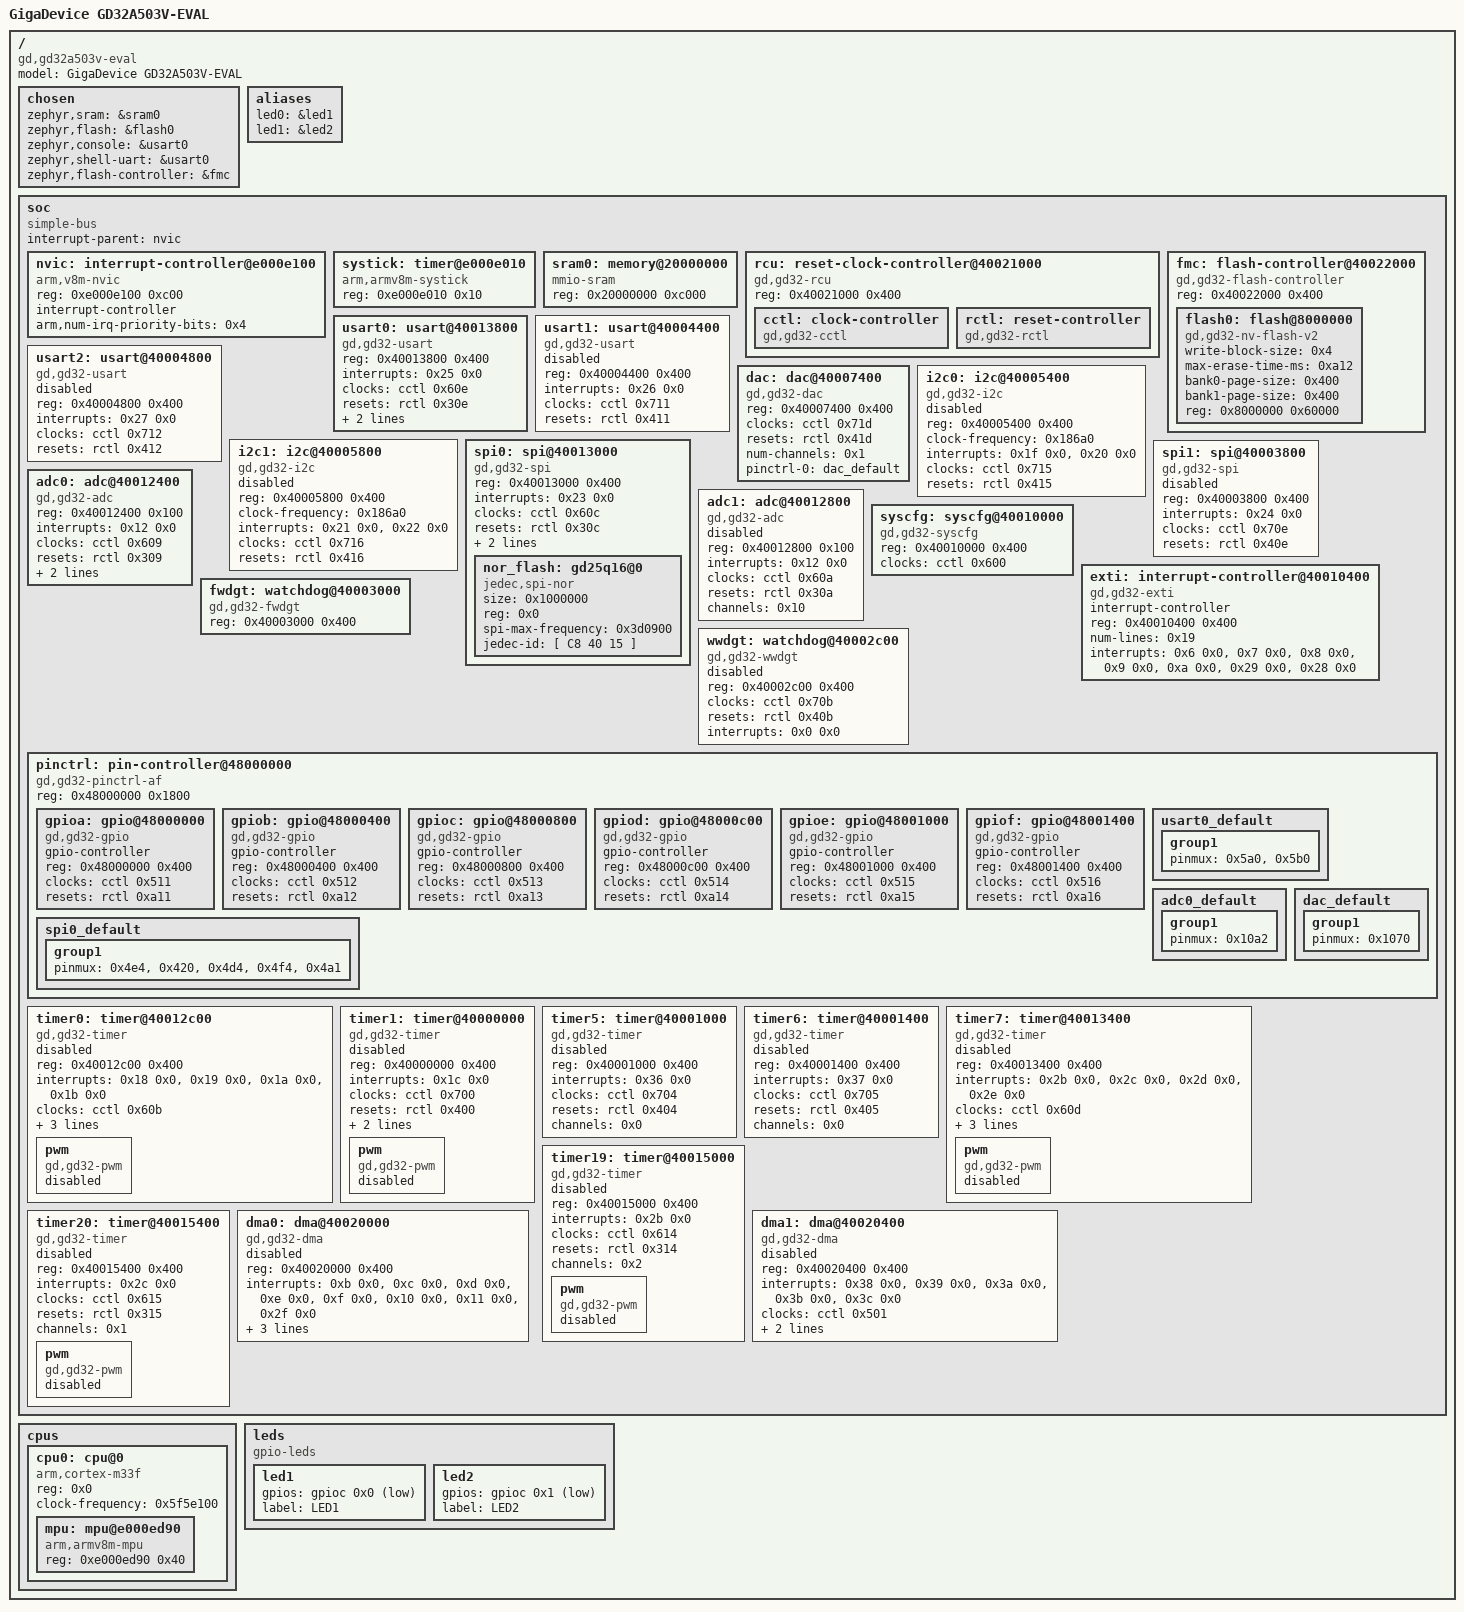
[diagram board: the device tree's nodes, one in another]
/dts-v1/;

/* node '/' defined in zephyr/dts/common/skeleton.dtsi:9 */
/ {
	#address-cells = < 0x1 >;            /* in zephyr/dts/common/skeleton.dtsi:10 */
	#size-cells = < 0x1 >;               /* in zephyr/dts/common/skeleton.dtsi:11 */
	model = "GigaDevice GD32A503V-EVAL"; /* in zephyr/boards/gd/gd32a503v_eval/gd32a503v_eval.dts:12 */
	compatible = "gd,gd32a503v-eval";    /* in zephyr/boards/gd/gd32a503v_eval/gd32a503v_eval.dts:13 */

	/* node '/chosen' defined in zephyr/dts/common/skeleton.dtsi:13 */
	chosen {
		zephyr,sram = &sram0;           /* in zephyr/boards/gd/gd32a503v_eval/gd32a503v_eval.dts:16 */
		zephyr,flash = &flash0;         /* in zephyr/boards/gd/gd32a503v_eval/gd32a503v_eval.dts:17 */
		zephyr,console = &usart0;       /* in zephyr/boards/gd/gd32a503v_eval/gd32a503v_eval.dts:18 */
		zephyr,shell-uart = &usart0;    /* in zephyr/boards/gd/gd32a503v_eval/gd32a503v_eval.dts:19 */
		zephyr,flash-controller = &fmc; /* in zephyr/boards/gd/gd32a503v_eval/gd32a503v_eval.dts:20 */
	};

	/* node '/aliases' defined in zephyr/dts/common/skeleton.dtsi:15 */
	aliases {
		led0 = &led1; /* in zephyr/boards/gd/gd32a503v_eval/gd32a503v_eval.dts:38 */
		led1 = &led2; /* in zephyr/boards/gd/gd32a503v_eval/gd32a503v_eval.dts:39 */
	};

	/* node '/soc' defined in zephyr/dts/arm/armv8-m.dtsi:6 */
	soc {
		#address-cells = < 0x1 >;     /* in zephyr/dts/arm/armv8-m.dtsi:7 */
		#size-cells = < 0x1 >;        /* in zephyr/dts/arm/armv8-m.dtsi:8 */
		compatible = "simple-bus";    /* in zephyr/dts/arm/armv8-m.dtsi:9 */
		interrupt-parent = < &nvic >; /* in zephyr/dts/arm/armv8-m.dtsi:10 */
		ranges;                       /* in zephyr/dts/arm/armv8-m.dtsi:11 */

		/* node '/soc/interrupt-controller@e000e100' defined in zephyr/dts/arm/armv8-m.dtsi:13 */
		nvic: interrupt-controller@e000e100 {
			#address-cells = < 0x1 >;            /* in zephyr/dts/arm/armv8-m.dtsi:14 */
			compatible = "arm,v8m-nvic";         /* in zephyr/dts/arm/armv8-m.dtsi:15 */
			reg = < 0xe000e100 0xc00 >;          /* in zephyr/dts/arm/armv8-m.dtsi:16 */
			interrupt-controller;                /* in zephyr/dts/arm/armv8-m.dtsi:17 */
			#interrupt-cells = < 0x2 >;          /* in zephyr/dts/arm/armv8-m.dtsi:18 */
			arm,num-irq-priority-bits = < 0x4 >; /* in zephyr/dts/arm/gd/gd32a50x/gd32a50x.dtsi:420 */
			phandle = < 0x1 >;                   /* in zephyr/dts/arm/armv8-m.dtsi:10 */
		};

		/* node '/soc/timer@e000e010' defined in zephyr/dts/arm/armv8-m.dtsi:21 */
		systick: timer@e000e010 {
			compatible = "arm,armv8m-systick"; /* in zephyr/dts/arm/armv8-m.dtsi:22 */
			reg = < 0xe000e010 0x10 >;         /* in zephyr/dts/arm/armv8-m.dtsi:23 */
		};

		/* node '/soc/memory@20000000' defined in zephyr/dts/arm/gd/gd32a50x/gd32a50x.dtsi:36 */
		sram0: memory@20000000 {
			compatible = "mmio-sram";    /* in zephyr/dts/arm/gd/gd32a50x/gd32a50x.dtsi:37 */
			reg = < 0x20000000 0xc000 >; /* in zephyr/dts/arm/gd/gd32a50x/gd32a503vdt3.dtsi:15 */
		};

		/* node '/soc/reset-clock-controller@40021000' defined in zephyr/dts/arm/gd/gd32a50x/gd32a50x.dtsi:40 */
		rcu: reset-clock-controller@40021000 {
			compatible = "gd,gd32-rcu"; /* in zephyr/dts/arm/gd/gd32a50x/gd32a50x.dtsi:41 */
			reg = < 0x40021000 0x400 >; /* in zephyr/dts/arm/gd/gd32a50x/gd32a50x.dtsi:42 */
			status = "okay";            /* in zephyr/dts/arm/gd/gd32a50x/gd32a50x.dtsi:43 */

			/* node '/soc/reset-clock-controller@40021000/clock-controller' defined in zephyr/dts/arm/gd/gd32a50x/gd32a50x.dtsi:45 */
			cctl: clock-controller {
				compatible = "gd,gd32-cctl"; /* in zephyr/dts/arm/gd/gd32a50x/gd32a50x.dtsi:46 */
				#clock-cells = < 0x1 >;      /* in zephyr/dts/arm/gd/gd32a50x/gd32a50x.dtsi:47 */
				status = "okay";             /* in zephyr/dts/arm/gd/gd32a50x/gd32a50x.dtsi:48 */
				phandle = < 0x2 >;           /* in zephyr/dts/arm/gd/gd32a50x/gd32a50x.dtsi:78 */
			};

			/* node '/soc/reset-clock-controller@40021000/reset-controller' defined in zephyr/dts/arm/gd/gd32a50x/gd32a50x.dtsi:51 */
			rctl: reset-controller {
				compatible = "gd,gd32-rctl"; /* in zephyr/dts/arm/gd/gd32a50x/gd32a50x.dtsi:52 */
				#reset-cells = < 0x1 >;      /* in zephyr/dts/arm/gd/gd32a50x/gd32a50x.dtsi:53 */
				status = "okay";             /* in zephyr/dts/arm/gd/gd32a50x/gd32a50x.dtsi:54 */
				phandle = < 0x3 >;           /* in zephyr/dts/arm/gd/gd32a50x/gd32a50x.dtsi:79 */
			};
		};

		/* node '/soc/flash-controller@40022000' defined in zephyr/dts/arm/gd/gd32a50x/gd32a50x.dtsi:58 */
		fmc: flash-controller@40022000 {
			compatible = "gd,gd32-flash-controller"; /* in zephyr/dts/arm/gd/gd32a50x/gd32a50x.dtsi:59 */
			reg = < 0x40022000 0x400 >;              /* in zephyr/dts/arm/gd/gd32a50x/gd32a50x.dtsi:60 */
			#address-cells = < 0x1 >;                /* in zephyr/dts/arm/gd/gd32a50x/gd32a50x.dtsi:62 */
			#size-cells = < 0x1 >;                   /* in zephyr/dts/arm/gd/gd32a50x/gd32a50x.dtsi:63 */

			/* node '/soc/flash-controller@40022000/flash@8000000' defined in zephyr/dts/arm/gd/gd32a50x/gd32a50x.dtsi:65 */
			flash0: flash@8000000 {
				compatible = "gd,gd32-nv-flash-v2",
				             "soc-nv-flash";        /* in zephyr/dts/arm/gd/gd32a50x/gd32a50x.dtsi:66 */
				write-block-size = < 0x4 >;         /* in zephyr/dts/arm/gd/gd32a50x/gd32a50x.dtsi:67 */
				max-erase-time-ms = < 0xa12 >;      /* in zephyr/dts/arm/gd/gd32a50x/gd32a50x.dtsi:68 */
				bank0-page-size = < 0x400 >;        /* in zephyr/dts/arm/gd/gd32a50x/gd32a50x.dtsi:69 */
				bank1-page-size = < 0x400 >;        /* in zephyr/dts/arm/gd/gd32a50x/gd32a50x.dtsi:70 */
				reg = < 0x8000000 0x60000 >;        /* in zephyr/dts/arm/gd/gd32a50x/gd32a503vdt3.dtsi:11 */
			};
		};

		/* node '/soc/usart@40013800' defined in zephyr/dts/arm/gd/gd32a50x/gd32a50x.dtsi:74 */
		usart0: usart@40013800 {
			compatible = "gd,gd32-usart";    /* in zephyr/dts/arm/gd/gd32a50x/gd32a50x.dtsi:75 */
			reg = < 0x40013800 0x400 >;      /* in zephyr/dts/arm/gd/gd32a50x/gd32a50x.dtsi:76 */
			interrupts = < 0x25 0x0 >;       /* in zephyr/dts/arm/gd/gd32a50x/gd32a50x.dtsi:77 */
			clocks = < &cctl 0x60e >;        /* in zephyr/dts/arm/gd/gd32a50x/gd32a50x.dtsi:78 */
			resets = < &rctl 0x30e >;        /* in zephyr/dts/arm/gd/gd32a50x/gd32a50x.dtsi:79 */
			status = "okay";                 /* in zephyr/boards/gd/gd32a503v_eval/gd32a503v_eval.dts:68 */
			current-speed = < 0x1c200 >;     /* in zephyr/boards/gd/gd32a503v_eval/gd32a503v_eval.dts:69 */
			pinctrl-0 = < &usart0_default >; /* in zephyr/boards/gd/gd32a503v_eval/gd32a503v_eval.dts:70 */
			pinctrl-names = "default";       /* in zephyr/boards/gd/gd32a503v_eval/gd32a503v_eval.dts:71 */
		};

		/* node '/soc/usart@40004400' defined in zephyr/dts/arm/gd/gd32a50x/gd32a50x.dtsi:83 */
		usart1: usart@40004400 {
			compatible = "gd,gd32-usart"; /* in zephyr/dts/arm/gd/gd32a50x/gd32a50x.dtsi:84 */
			reg = < 0x40004400 0x400 >;   /* in zephyr/dts/arm/gd/gd32a50x/gd32a50x.dtsi:85 */
			interrupts = < 0x26 0x0 >;    /* in zephyr/dts/arm/gd/gd32a50x/gd32a50x.dtsi:86 */
			clocks = < &cctl 0x711 >;     /* in zephyr/dts/arm/gd/gd32a50x/gd32a50x.dtsi:87 */
			resets = < &rctl 0x411 >;     /* in zephyr/dts/arm/gd/gd32a50x/gd32a50x.dtsi:88 */
			status = "disabled";          /* in zephyr/dts/arm/gd/gd32a50x/gd32a50x.dtsi:89 */
		};

		/* node '/soc/usart@40004800' defined in zephyr/dts/arm/gd/gd32a50x/gd32a50x.dtsi:92 */
		usart2: usart@40004800 {
			compatible = "gd,gd32-usart"; /* in zephyr/dts/arm/gd/gd32a50x/gd32a50x.dtsi:93 */
			reg = < 0x40004800 0x400 >;   /* in zephyr/dts/arm/gd/gd32a50x/gd32a50x.dtsi:94 */
			interrupts = < 0x27 0x0 >;    /* in zephyr/dts/arm/gd/gd32a50x/gd32a50x.dtsi:95 */
			clocks = < &cctl 0x712 >;     /* in zephyr/dts/arm/gd/gd32a50x/gd32a50x.dtsi:96 */
			resets = < &rctl 0x412 >;     /* in zephyr/dts/arm/gd/gd32a50x/gd32a50x.dtsi:97 */
			status = "disabled";          /* in zephyr/dts/arm/gd/gd32a50x/gd32a50x.dtsi:98 */
		};

		/* node '/soc/dac@40007400' defined in zephyr/dts/arm/gd/gd32a50x/gd32a50x.dtsi:101 */
		dac: dac@40007400 {
			compatible = "gd,gd32-dac";   /* in zephyr/dts/arm/gd/gd32a50x/gd32a50x.dtsi:102 */
			reg = < 0x40007400 0x400 >;   /* in zephyr/dts/arm/gd/gd32a50x/gd32a50x.dtsi:103 */
			clocks = < &cctl 0x71d >;     /* in zephyr/dts/arm/gd/gd32a50x/gd32a50x.dtsi:104 */
			resets = < &rctl 0x41d >;     /* in zephyr/dts/arm/gd/gd32a50x/gd32a50x.dtsi:105 */
			num-channels = < 0x1 >;       /* in zephyr/dts/arm/gd/gd32a50x/gd32a50x.dtsi:106 */
			#io-channel-cells = < 0x1 >;  /* in zephyr/dts/arm/gd/gd32a50x/gd32a50x.dtsi:108 */
			status = "okay";              /* in zephyr/boards/gd/gd32a503v_eval/gd32a503v_eval.dts:81 */
			pinctrl-0 = < &dac_default >; /* in zephyr/boards/gd/gd32a503v_eval/gd32a503v_eval.dts:82 */
			pinctrl-names = "default";    /* in zephyr/boards/gd/gd32a503v_eval/gd32a503v_eval.dts:83 */
		};

		/* node '/soc/i2c@40005400' defined in zephyr/dts/arm/gd/gd32a50x/gd32a50x.dtsi:111 */
		i2c0: i2c@40005400 {
			compatible = "gd,gd32-i2c";    /* in zephyr/dts/arm/gd/gd32a50x/gd32a50x.dtsi:112 */
			reg = < 0x40005400 0x400 >;    /* in zephyr/dts/arm/gd/gd32a50x/gd32a50x.dtsi:113 */
			#address-cells = < 0x1 >;      /* in zephyr/dts/arm/gd/gd32a50x/gd32a50x.dtsi:114 */
			#size-cells = < 0x0 >;         /* in zephyr/dts/arm/gd/gd32a50x/gd32a50x.dtsi:115 */
			clock-frequency = < 0x186a0 >; /* in zephyr/dts/arm/gd/gd32a50x/gd32a50x.dtsi:116 */
			interrupts = < 0x1f 0x0 >,
			             < 0x20 0x0 >;     /* in zephyr/dts/arm/gd/gd32a50x/gd32a50x.dtsi:117 */
			interrupt-names = "event",
			                  "error";     /* in zephyr/dts/arm/gd/gd32a50x/gd32a50x.dtsi:118 */
			clocks = < &cctl 0x715 >;      /* in zephyr/dts/arm/gd/gd32a50x/gd32a50x.dtsi:119 */
			resets = < &rctl 0x415 >;      /* in zephyr/dts/arm/gd/gd32a50x/gd32a50x.dtsi:120 */
			status = "disabled";           /* in zephyr/dts/arm/gd/gd32a50x/gd32a50x.dtsi:121 */
		};

		/* node '/soc/i2c@40005800' defined in zephyr/dts/arm/gd/gd32a50x/gd32a50x.dtsi:124 */
		i2c1: i2c@40005800 {
			compatible = "gd,gd32-i2c";    /* in zephyr/dts/arm/gd/gd32a50x/gd32a50x.dtsi:125 */
			reg = < 0x40005800 0x400 >;    /* in zephyr/dts/arm/gd/gd32a50x/gd32a50x.dtsi:126 */
			#address-cells = < 0x1 >;      /* in zephyr/dts/arm/gd/gd32a50x/gd32a50x.dtsi:127 */
			#size-cells = < 0x0 >;         /* in zephyr/dts/arm/gd/gd32a50x/gd32a50x.dtsi:128 */
			clock-frequency = < 0x186a0 >; /* in zephyr/dts/arm/gd/gd32a50x/gd32a50x.dtsi:129 */
			interrupts = < 0x21 0x0 >,
			             < 0x22 0x0 >;     /* in zephyr/dts/arm/gd/gd32a50x/gd32a50x.dtsi:130 */
			interrupt-names = "event",
			                  "error";     /* in zephyr/dts/arm/gd/gd32a50x/gd32a50x.dtsi:131 */
			clocks = < &cctl 0x716 >;      /* in zephyr/dts/arm/gd/gd32a50x/gd32a50x.dtsi:132 */
			resets = < &rctl 0x416 >;      /* in zephyr/dts/arm/gd/gd32a50x/gd32a50x.dtsi:133 */
			status = "disabled";           /* in zephyr/dts/arm/gd/gd32a50x/gd32a50x.dtsi:134 */
		};

		/* node '/soc/spi@40013000' defined in zephyr/dts/arm/gd/gd32a50x/gd32a50x.dtsi:137 */
		spi0: spi@40013000 {
			compatible = "gd,gd32-spi";    /* in zephyr/dts/arm/gd/gd32a50x/gd32a50x.dtsi:138 */
			reg = < 0x40013000 0x400 >;    /* in zephyr/dts/arm/gd/gd32a50x/gd32a50x.dtsi:139 */
			interrupts = < 0x23 0x0 >;     /* in zephyr/dts/arm/gd/gd32a50x/gd32a50x.dtsi:140 */
			clocks = < &cctl 0x60c >;      /* in zephyr/dts/arm/gd/gd32a50x/gd32a50x.dtsi:141 */
			resets = < &rctl 0x30c >;      /* in zephyr/dts/arm/gd/gd32a50x/gd32a50x.dtsi:142 */
			#address-cells = < 0x1 >;      /* in zephyr/dts/arm/gd/gd32a50x/gd32a50x.dtsi:144 */
			#size-cells = < 0x0 >;         /* in zephyr/dts/arm/gd/gd32a50x/gd32a50x.dtsi:145 */
			status = "okay";               /* in zephyr/boards/gd/gd32a503v_eval/gd32a503v_eval.dts:91 */
			pinctrl-0 = < &spi0_default >; /* in zephyr/boards/gd/gd32a503v_eval/gd32a503v_eval.dts:92 */
			pinctrl-names = "default";     /* in zephyr/boards/gd/gd32a503v_eval/gd32a503v_eval.dts:93 */
			cs-gpios = < &gpioa 0x1 0x1 >; /* in zephyr/boards/gd/gd32a503v_eval/gd32a503v_eval.dts:94 */

			/* node '/soc/spi@40013000/gd25q16@0' defined in zephyr/boards/gd/gd32a503v_eval/gd32a503v_eval.dts:96 */
			nor_flash: gd25q16@0 {
				compatible = "jedec,spi-nor";     /* in zephyr/boards/gd/gd32a503v_eval/gd32a503v_eval.dts:97 */
				size = < 0x1000000 >;             /* in zephyr/boards/gd/gd32a503v_eval/gd32a503v_eval.dts:98 */
				reg = < 0x0 >;                    /* in zephyr/boards/gd/gd32a503v_eval/gd32a503v_eval.dts:99 */
				spi-max-frequency = < 0x3d0900 >; /* in zephyr/boards/gd/gd32a503v_eval/gd32a503v_eval.dts:100 */
				status = "okay";                  /* in zephyr/boards/gd/gd32a503v_eval/gd32a503v_eval.dts:101 */
				jedec-id = [ C8 40 15 ];          /* in zephyr/boards/gd/gd32a503v_eval/gd32a503v_eval.dts:102 */
			};
		};

		/* node '/soc/spi@40003800' defined in zephyr/dts/arm/gd/gd32a50x/gd32a50x.dtsi:148 */
		spi1: spi@40003800 {
			compatible = "gd,gd32-spi"; /* in zephyr/dts/arm/gd/gd32a50x/gd32a50x.dtsi:149 */
			reg = < 0x40003800 0x400 >; /* in zephyr/dts/arm/gd/gd32a50x/gd32a50x.dtsi:150 */
			interrupts = < 0x24 0x0 >;  /* in zephyr/dts/arm/gd/gd32a50x/gd32a50x.dtsi:151 */
			clocks = < &cctl 0x70e >;   /* in zephyr/dts/arm/gd/gd32a50x/gd32a50x.dtsi:152 */
			resets = < &rctl 0x40e >;   /* in zephyr/dts/arm/gd/gd32a50x/gd32a50x.dtsi:153 */
			status = "disabled";        /* in zephyr/dts/arm/gd/gd32a50x/gd32a50x.dtsi:154 */
			#address-cells = < 0x1 >;   /* in zephyr/dts/arm/gd/gd32a50x/gd32a50x.dtsi:155 */
			#size-cells = < 0x0 >;      /* in zephyr/dts/arm/gd/gd32a50x/gd32a50x.dtsi:156 */
		};

		/* node '/soc/adc@40012400' defined in zephyr/dts/arm/gd/gd32a50x/gd32a50x.dtsi:159 */
		adc0: adc@40012400 {
			compatible = "gd,gd32-adc";    /* in zephyr/dts/arm/gd/gd32a50x/gd32a50x.dtsi:160 */
			reg = < 0x40012400 0x100 >;    /* in zephyr/dts/arm/gd/gd32a50x/gd32a50x.dtsi:161 */
			interrupts = < 0x12 0x0 >;     /* in zephyr/dts/arm/gd/gd32a50x/gd32a50x.dtsi:162 */
			clocks = < &cctl 0x609 >;      /* in zephyr/dts/arm/gd/gd32a50x/gd32a50x.dtsi:163 */
			resets = < &rctl 0x309 >;      /* in zephyr/dts/arm/gd/gd32a50x/gd32a50x.dtsi:164 */
			channels = < 0x10 >;           /* in zephyr/dts/arm/gd/gd32a50x/gd32a50x.dtsi:165 */
			#io-channel-cells = < 0x1 >;   /* in zephyr/dts/arm/gd/gd32a50x/gd32a50x.dtsi:167 */
			status = "okay";               /* in zephyr/boards/gd/gd32a503v_eval/gd32a503v_eval.dts:75 */
			pinctrl-0 = < &adc0_default >; /* in zephyr/boards/gd/gd32a503v_eval/gd32a503v_eval.dts:76 */
			pinctrl-names = "default";     /* in zephyr/boards/gd/gd32a503v_eval/gd32a503v_eval.dts:77 */
		};

		/* node '/soc/adc@40012800' defined in zephyr/dts/arm/gd/gd32a50x/gd32a50x.dtsi:170 */
		adc1: adc@40012800 {
			compatible = "gd,gd32-adc";  /* in zephyr/dts/arm/gd/gd32a50x/gd32a50x.dtsi:171 */
			reg = < 0x40012800 0x100 >;  /* in zephyr/dts/arm/gd/gd32a50x/gd32a50x.dtsi:172 */
			interrupts = < 0x12 0x0 >;   /* in zephyr/dts/arm/gd/gd32a50x/gd32a50x.dtsi:173 */
			clocks = < &cctl 0x60a >;    /* in zephyr/dts/arm/gd/gd32a50x/gd32a50x.dtsi:174 */
			resets = < &rctl 0x30a >;    /* in zephyr/dts/arm/gd/gd32a50x/gd32a50x.dtsi:175 */
			channels = < 0x10 >;         /* in zephyr/dts/arm/gd/gd32a50x/gd32a50x.dtsi:176 */
			status = "disabled";         /* in zephyr/dts/arm/gd/gd32a50x/gd32a50x.dtsi:177 */
			#io-channel-cells = < 0x1 >; /* in zephyr/dts/arm/gd/gd32a50x/gd32a50x.dtsi:178 */
		};

		/* node '/soc/syscfg@40010000' defined in zephyr/dts/arm/gd/gd32a50x/gd32a50x.dtsi:181 */
		syscfg: syscfg@40010000 {
			compatible = "gd,gd32-syscfg"; /* in zephyr/dts/arm/gd/gd32a50x/gd32a50x.dtsi:182 */
			reg = < 0x40010000 0x400 >;    /* in zephyr/dts/arm/gd/gd32a50x/gd32a50x.dtsi:183 */
			clocks = < &cctl 0x600 >;      /* in zephyr/dts/arm/gd/gd32a50x/gd32a50x.dtsi:184 */
		};

		/* node '/soc/interrupt-controller@40010400' defined in zephyr/dts/arm/gd/gd32a50x/gd32a50x.dtsi:187 */
		exti: interrupt-controller@40010400 {
			compatible = "gd,gd32-exti";   /* in zephyr/dts/arm/gd/gd32a50x/gd32a50x.dtsi:188 */
			interrupt-controller;          /* in zephyr/dts/arm/gd/gd32a50x/gd32a50x.dtsi:189 */
			#interrupt-cells = < 0x1 >;    /* in zephyr/dts/arm/gd/gd32a50x/gd32a50x.dtsi:190 */
			reg = < 0x40010400 0x400 >;    /* in zephyr/dts/arm/gd/gd32a50x/gd32a50x.dtsi:191 */
			num-lines = < 0x19 >;          /* in zephyr/dts/arm/gd/gd32a50x/gd32a50x.dtsi:192 */
			interrupts = < 0x6 0x0 >,
			             < 0x7 0x0 >,
			             < 0x8 0x0 >,
			             < 0x9 0x0 >,
			             < 0xa 0x0 >,
			             < 0x29 0x0 >,
			             < 0x28 0x0 >;     /* in zephyr/dts/arm/gd/gd32a50x/gd32a50x.dtsi:193 */
			interrupt-names = "line0",
			                  "line1",
			                  "line2",
			                  "line3",
			                  "line4",
			                  "line5-9",
			                  "line10-15"; /* in zephyr/dts/arm/gd/gd32a50x/gd32a50x.dtsi:195 */
			status = "okay";               /* in zephyr/dts/arm/gd/gd32a50x/gd32a50x.dtsi:197 */
		};

		/* node '/soc/watchdog@40003000' defined in zephyr/dts/arm/gd/gd32a50x/gd32a50x.dtsi:200 */
		fwdgt: watchdog@40003000 {
			compatible = "gd,gd32-fwdgt"; /* in zephyr/dts/arm/gd/gd32a50x/gd32a50x.dtsi:201 */
			reg = < 0x40003000 0x400 >;   /* in zephyr/dts/arm/gd/gd32a50x/gd32a50x.dtsi:202 */
			status = "okay";              /* in zephyr/boards/gd/gd32a503v_eval/gd32a503v_eval.dts:87 */
		};

		/* node '/soc/watchdog@40002c00' defined in zephyr/dts/arm/gd/gd32a50x/gd32a50x.dtsi:206 */
		wwdgt: watchdog@40002c00 {
			compatible = "gd,gd32-wwdgt"; /* in zephyr/dts/arm/gd/gd32a50x/gd32a50x.dtsi:207 */
			reg = < 0x40002c00 0x400 >;   /* in zephyr/dts/arm/gd/gd32a50x/gd32a50x.dtsi:208 */
			clocks = < &cctl 0x70b >;     /* in zephyr/dts/arm/gd/gd32a50x/gd32a50x.dtsi:209 */
			resets = < &rctl 0x40b >;     /* in zephyr/dts/arm/gd/gd32a50x/gd32a50x.dtsi:210 */
			interrupts = < 0x0 0x0 >;     /* in zephyr/dts/arm/gd/gd32a50x/gd32a50x.dtsi:211 */
			status = "disabled";          /* in zephyr/dts/arm/gd/gd32a50x/gd32a50x.dtsi:212 */
		};

		/* node '/soc/pin-controller@48000000' defined in zephyr/dts/arm/gd/gd32a50x/gd32a50x.dtsi:215 */
		pinctrl: pin-controller@48000000 {
			compatible = "gd,gd32-pinctrl-af"; /* in zephyr/dts/arm/gd/gd32a50x/gd32a50x.dtsi:216 */
			reg = < 0x48000000 0x1800 >;       /* in zephyr/dts/arm/gd/gd32a50x/gd32a50x.dtsi:217 */
			#address-cells = < 0x1 >;          /* in zephyr/dts/arm/gd/gd32a50x/gd32a50x.dtsi:218 */
			#size-cells = < 0x1 >;             /* in zephyr/dts/arm/gd/gd32a50x/gd32a50x.dtsi:219 */
			status = "okay";                   /* in zephyr/dts/arm/gd/gd32a50x/gd32a50x.dtsi:220 */

			/* node '/soc/pin-controller@48000000/gpio@48000000' defined in zephyr/dts/arm/gd/gd32a50x/gd32a50x.dtsi:222 */
			gpioa: gpio@48000000 {
				compatible = "gd,gd32-gpio"; /* in zephyr/dts/arm/gd/gd32a50x/gd32a50x.dtsi:223 */
				gpio-controller;             /* in zephyr/dts/arm/gd/gd32a50x/gd32a50x.dtsi:224 */
				#gpio-cells = < 0x2 >;       /* in zephyr/dts/arm/gd/gd32a50x/gd32a50x.dtsi:225 */
				reg = < 0x48000000 0x400 >;  /* in zephyr/dts/arm/gd/gd32a50x/gd32a50x.dtsi:226 */
				clocks = < &cctl 0x511 >;    /* in zephyr/dts/arm/gd/gd32a50x/gd32a50x.dtsi:227 */
				resets = < &rctl 0xa11 >;    /* in zephyr/dts/arm/gd/gd32a50x/gd32a50x.dtsi:228 */
				status = "okay";             /* in zephyr/boards/gd/gd32a503v_eval/gd32a503v_eval.dts:44 */
				phandle = < 0x7 >;           /* in zephyr/boards/gd/gd32a503v_eval/gd32a503v_eval.dts:94 */
			};

			/* node '/soc/pin-controller@48000000/gpio@48000400' defined in zephyr/dts/arm/gd/gd32a50x/gd32a50x.dtsi:232 */
			gpiob: gpio@48000400 {
				compatible = "gd,gd32-gpio"; /* in zephyr/dts/arm/gd/gd32a50x/gd32a50x.dtsi:233 */
				gpio-controller;             /* in zephyr/dts/arm/gd/gd32a50x/gd32a50x.dtsi:234 */
				#gpio-cells = < 0x2 >;       /* in zephyr/dts/arm/gd/gd32a50x/gd32a50x.dtsi:235 */
				reg = < 0x48000400 0x400 >;  /* in zephyr/dts/arm/gd/gd32a50x/gd32a50x.dtsi:236 */
				clocks = < &cctl 0x512 >;    /* in zephyr/dts/arm/gd/gd32a50x/gd32a50x.dtsi:237 */
				resets = < &rctl 0xa12 >;    /* in zephyr/dts/arm/gd/gd32a50x/gd32a50x.dtsi:238 */
				status = "okay";             /* in zephyr/boards/gd/gd32a503v_eval/gd32a503v_eval.dts:48 */
			};

			/* node '/soc/pin-controller@48000000/gpio@48000800' defined in zephyr/dts/arm/gd/gd32a50x/gd32a50x.dtsi:242 */
			gpioc: gpio@48000800 {
				compatible = "gd,gd32-gpio"; /* in zephyr/dts/arm/gd/gd32a50x/gd32a50x.dtsi:243 */
				gpio-controller;             /* in zephyr/dts/arm/gd/gd32a50x/gd32a50x.dtsi:244 */
				#gpio-cells = < 0x2 >;       /* in zephyr/dts/arm/gd/gd32a50x/gd32a50x.dtsi:245 */
				reg = < 0x48000800 0x400 >;  /* in zephyr/dts/arm/gd/gd32a50x/gd32a50x.dtsi:246 */
				clocks = < &cctl 0x513 >;    /* in zephyr/dts/arm/gd/gd32a50x/gd32a50x.dtsi:247 */
				resets = < &rctl 0xa13 >;    /* in zephyr/dts/arm/gd/gd32a50x/gd32a50x.dtsi:248 */
				status = "okay";             /* in zephyr/boards/gd/gd32a503v_eval/gd32a503v_eval.dts:52 */
				phandle = < 0x9 >;           /* in zephyr/boards/gd/gd32a503v_eval/gd32a503v_eval.dts:27 */
			};

			/* node '/soc/pin-controller@48000000/gpio@48000c00' defined in zephyr/dts/arm/gd/gd32a50x/gd32a50x.dtsi:252 */
			gpiod: gpio@48000c00 {
				compatible = "gd,gd32-gpio"; /* in zephyr/dts/arm/gd/gd32a50x/gd32a50x.dtsi:253 */
				gpio-controller;             /* in zephyr/dts/arm/gd/gd32a50x/gd32a50x.dtsi:254 */
				#gpio-cells = < 0x2 >;       /* in zephyr/dts/arm/gd/gd32a50x/gd32a50x.dtsi:255 */
				reg = < 0x48000c00 0x400 >;  /* in zephyr/dts/arm/gd/gd32a50x/gd32a50x.dtsi:256 */
				clocks = < &cctl 0x514 >;    /* in zephyr/dts/arm/gd/gd32a50x/gd32a50x.dtsi:257 */
				resets = < &rctl 0xa14 >;    /* in zephyr/dts/arm/gd/gd32a50x/gd32a50x.dtsi:258 */
				status = "okay";             /* in zephyr/boards/gd/gd32a503v_eval/gd32a503v_eval.dts:56 */
			};

			/* node '/soc/pin-controller@48000000/gpio@48001000' defined in zephyr/dts/arm/gd/gd32a50x/gd32a50x.dtsi:262 */
			gpioe: gpio@48001000 {
				compatible = "gd,gd32-gpio"; /* in zephyr/dts/arm/gd/gd32a50x/gd32a50x.dtsi:263 */
				gpio-controller;             /* in zephyr/dts/arm/gd/gd32a50x/gd32a50x.dtsi:264 */
				#gpio-cells = < 0x2 >;       /* in zephyr/dts/arm/gd/gd32a50x/gd32a50x.dtsi:265 */
				reg = < 0x48001000 0x400 >;  /* in zephyr/dts/arm/gd/gd32a50x/gd32a50x.dtsi:266 */
				clocks = < &cctl 0x515 >;    /* in zephyr/dts/arm/gd/gd32a50x/gd32a50x.dtsi:267 */
				resets = < &rctl 0xa15 >;    /* in zephyr/dts/arm/gd/gd32a50x/gd32a50x.dtsi:268 */
				status = "okay";             /* in zephyr/boards/gd/gd32a503v_eval/gd32a503v_eval.dts:60 */
			};

			/* node '/soc/pin-controller@48000000/gpio@48001400' defined in zephyr/dts/arm/gd/gd32a50x/gd32a50x.dtsi:272 */
			gpiof: gpio@48001400 {
				compatible = "gd,gd32-gpio"; /* in zephyr/dts/arm/gd/gd32a50x/gd32a50x.dtsi:273 */
				gpio-controller;             /* in zephyr/dts/arm/gd/gd32a50x/gd32a50x.dtsi:274 */
				#gpio-cells = < 0x2 >;       /* in zephyr/dts/arm/gd/gd32a50x/gd32a50x.dtsi:275 */
				reg = < 0x48001400 0x400 >;  /* in zephyr/dts/arm/gd/gd32a50x/gd32a50x.dtsi:276 */
				clocks = < &cctl 0x516 >;    /* in zephyr/dts/arm/gd/gd32a50x/gd32a50x.dtsi:277 */
				resets = < &rctl 0xa16 >;    /* in zephyr/dts/arm/gd/gd32a50x/gd32a50x.dtsi:278 */
				status = "okay";             /* in zephyr/boards/gd/gd32a503v_eval/gd32a503v_eval.dts:64 */
			};

			/* node '/soc/pin-controller@48000000/usart0_default' defined in zephyr/boards/gd/gd32a503v_eval/gd32a503v_eval-pinctrl.dtsi:9 */
			usart0_default: usart0_default {
				phandle = < 0x4 >; /* in zephyr/boards/gd/gd32a503v_eval/gd32a503v_eval.dts:70 */

				/* node '/soc/pin-controller@48000000/usart0_default/group1' defined in zephyr/boards/gd/gd32a503v_eval/gd32a503v_eval-pinctrl.dtsi:10 */
				group1 {
					pinmux = < 0x5a0 >,
					         < 0x5b0 >; /* in zephyr/boards/gd/gd32a503v_eval/gd32a503v_eval-pinctrl.dtsi:11 */
				};
			};

			/* node '/soc/pin-controller@48000000/adc0_default' defined in zephyr/boards/gd/gd32a503v_eval/gd32a503v_eval-pinctrl.dtsi:15 */
			adc0_default: adc0_default {
				phandle = < 0x8 >; /* in zephyr/boards/gd/gd32a503v_eval/gd32a503v_eval.dts:76 */

				/* node '/soc/pin-controller@48000000/adc0_default/group1' defined in zephyr/boards/gd/gd32a503v_eval/gd32a503v_eval-pinctrl.dtsi:16 */
				group1 {
					pinmux = < 0x10a2 >; /* in zephyr/boards/gd/gd32a503v_eval/gd32a503v_eval-pinctrl.dtsi:17 */
				};
			};

			/* node '/soc/pin-controller@48000000/dac_default' defined in zephyr/boards/gd/gd32a503v_eval/gd32a503v_eval-pinctrl.dtsi:21 */
			dac_default: dac_default {
				phandle = < 0x5 >; /* in zephyr/boards/gd/gd32a503v_eval/gd32a503v_eval.dts:82 */

				/* node '/soc/pin-controller@48000000/dac_default/group1' defined in zephyr/boards/gd/gd32a503v_eval/gd32a503v_eval-pinctrl.dtsi:22 */
				group1 {
					pinmux = < 0x1070 >; /* in zephyr/boards/gd/gd32a503v_eval/gd32a503v_eval-pinctrl.dtsi:23 */
				};
			};

			/* node '/soc/pin-controller@48000000/spi0_default' defined in zephyr/boards/gd/gd32a503v_eval/gd32a503v_eval-pinctrl.dtsi:27 */
			spi0_default: spi0_default {
				phandle = < 0x6 >; /* in zephyr/boards/gd/gd32a503v_eval/gd32a503v_eval.dts:92 */

				/* node '/soc/pin-controller@48000000/spi0_default/group1' defined in zephyr/boards/gd/gd32a503v_eval/gd32a503v_eval-pinctrl.dtsi:28 */
				group1 {
					pinmux = < 0x4e4 >,
					         < 0x420 >,
					         < 0x4d4 >,
					         < 0x4f4 >,
					         < 0x4a1 >; /* in zephyr/boards/gd/gd32a503v_eval/gd32a503v_eval-pinctrl.dtsi:29 */
				};
			};
		};

		/* node '/soc/timer@40012c00' defined in zephyr/dts/arm/gd/gd32a50x/gd32a50x.dtsi:283 */
		timer0: timer@40012c00 {
			compatible = "gd,gd32-timer"; /* in zephyr/dts/arm/gd/gd32a50x/gd32a50x.dtsi:284 */
			reg = < 0x40012c00 0x400 >;   /* in zephyr/dts/arm/gd/gd32a50x/gd32a50x.dtsi:285 */
			interrupts = < 0x18 0x0 >,
			             < 0x19 0x0 >,
			             < 0x1a 0x0 >,
			             < 0x1b 0x0 >;    /* in zephyr/dts/arm/gd/gd32a50x/gd32a50x.dtsi:286 */
			interrupt-names = "brk",
			                  "up",
			                  "trgcom",
			                  "cc";       /* in zephyr/dts/arm/gd/gd32a50x/gd32a50x.dtsi:287 */
			clocks = < &cctl 0x60b >;     /* in zephyr/dts/arm/gd/gd32a50x/gd32a50x.dtsi:288 */
			resets = < &rctl 0x30b >;     /* in zephyr/dts/arm/gd/gd32a50x/gd32a50x.dtsi:289 */
			is-advanced;                  /* in zephyr/dts/arm/gd/gd32a50x/gd32a50x.dtsi:290 */
			channels = < 0x4 >;           /* in zephyr/dts/arm/gd/gd32a50x/gd32a50x.dtsi:291 */
			status = "disabled";          /* in zephyr/dts/arm/gd/gd32a50x/gd32a50x.dtsi:292 */

			/* node '/soc/timer@40012c00/pwm' defined in zephyr/dts/arm/gd/gd32a50x/gd32a50x.dtsi:294 */
			pwm {
				compatible = "gd,gd32-pwm"; /* in zephyr/dts/arm/gd/gd32a50x/gd32a50x.dtsi:295 */
				status = "disabled";        /* in zephyr/dts/arm/gd/gd32a50x/gd32a50x.dtsi:296 */
				#pwm-cells = < 0x3 >;       /* in zephyr/dts/arm/gd/gd32a50x/gd32a50x.dtsi:297 */
			};
		};

		/* node '/soc/timer@40000000' defined in zephyr/dts/arm/gd/gd32a50x/gd32a50x.dtsi:301 */
		timer1: timer@40000000 {
			compatible = "gd,gd32-timer"; /* in zephyr/dts/arm/gd/gd32a50x/gd32a50x.dtsi:302 */
			reg = < 0x40000000 0x400 >;   /* in zephyr/dts/arm/gd/gd32a50x/gd32a50x.dtsi:303 */
			interrupts = < 0x1c 0x0 >;    /* in zephyr/dts/arm/gd/gd32a50x/gd32a50x.dtsi:304 */
			interrupt-names = "global";   /* in zephyr/dts/arm/gd/gd32a50x/gd32a50x.dtsi:305 */
			clocks = < &cctl 0x700 >;     /* in zephyr/dts/arm/gd/gd32a50x/gd32a50x.dtsi:306 */
			resets = < &rctl 0x400 >;     /* in zephyr/dts/arm/gd/gd32a50x/gd32a50x.dtsi:307 */
			is-32bit;                     /* in zephyr/dts/arm/gd/gd32a50x/gd32a50x.dtsi:308 */
			channels = < 0x4 >;           /* in zephyr/dts/arm/gd/gd32a50x/gd32a50x.dtsi:309 */
			status = "disabled";          /* in zephyr/dts/arm/gd/gd32a50x/gd32a50x.dtsi:310 */

			/* node '/soc/timer@40000000/pwm' defined in zephyr/dts/arm/gd/gd32a50x/gd32a50x.dtsi:312 */
			pwm {
				compatible = "gd,gd32-pwm"; /* in zephyr/dts/arm/gd/gd32a50x/gd32a50x.dtsi:313 */
				status = "disabled";        /* in zephyr/dts/arm/gd/gd32a50x/gd32a50x.dtsi:314 */
				#pwm-cells = < 0x3 >;       /* in zephyr/dts/arm/gd/gd32a50x/gd32a50x.dtsi:315 */
			};
		};

		/* node '/soc/timer@40001000' defined in zephyr/dts/arm/gd/gd32a50x/gd32a50x.dtsi:319 */
		timer5: timer@40001000 {
			compatible = "gd,gd32-timer"; /* in zephyr/dts/arm/gd/gd32a50x/gd32a50x.dtsi:320 */
			reg = < 0x40001000 0x400 >;   /* in zephyr/dts/arm/gd/gd32a50x/gd32a50x.dtsi:321 */
			interrupts = < 0x36 0x0 >;    /* in zephyr/dts/arm/gd/gd32a50x/gd32a50x.dtsi:322 */
			interrupt-names = "global";   /* in zephyr/dts/arm/gd/gd32a50x/gd32a50x.dtsi:323 */
			clocks = < &cctl 0x704 >;     /* in zephyr/dts/arm/gd/gd32a50x/gd32a50x.dtsi:324 */
			resets = < &rctl 0x404 >;     /* in zephyr/dts/arm/gd/gd32a50x/gd32a50x.dtsi:325 */
			channels = < 0x0 >;           /* in zephyr/dts/arm/gd/gd32a50x/gd32a50x.dtsi:326 */
			status = "disabled";          /* in zephyr/dts/arm/gd/gd32a50x/gd32a50x.dtsi:327 */
		};

		/* node '/soc/timer@40001400' defined in zephyr/dts/arm/gd/gd32a50x/gd32a50x.dtsi:330 */
		timer6: timer@40001400 {
			compatible = "gd,gd32-timer"; /* in zephyr/dts/arm/gd/gd32a50x/gd32a50x.dtsi:331 */
			reg = < 0x40001400 0x400 >;   /* in zephyr/dts/arm/gd/gd32a50x/gd32a50x.dtsi:332 */
			interrupts = < 0x37 0x0 >;    /* in zephyr/dts/arm/gd/gd32a50x/gd32a50x.dtsi:333 */
			interrupt-names = "global";   /* in zephyr/dts/arm/gd/gd32a50x/gd32a50x.dtsi:334 */
			clocks = < &cctl 0x705 >;     /* in zephyr/dts/arm/gd/gd32a50x/gd32a50x.dtsi:335 */
			resets = < &rctl 0x405 >;     /* in zephyr/dts/arm/gd/gd32a50x/gd32a50x.dtsi:336 */
			channels = < 0x0 >;           /* in zephyr/dts/arm/gd/gd32a50x/gd32a50x.dtsi:337 */
			status = "disabled";          /* in zephyr/dts/arm/gd/gd32a50x/gd32a50x.dtsi:338 */
		};

		/* node '/soc/timer@40013400' defined in zephyr/dts/arm/gd/gd32a50x/gd32a50x.dtsi:341 */
		timer7: timer@40013400 {
			compatible = "gd,gd32-timer"; /* in zephyr/dts/arm/gd/gd32a50x/gd32a50x.dtsi:342 */
			reg = < 0x40013400 0x400 >;   /* in zephyr/dts/arm/gd/gd32a50x/gd32a50x.dtsi:343 */
			interrupts = < 0x2b 0x0 >,
			             < 0x2c 0x0 >,
			             < 0x2d 0x0 >,
			             < 0x2e 0x0 >;    /* in zephyr/dts/arm/gd/gd32a50x/gd32a50x.dtsi:344 */
			interrupt-names = "brk",
			                  "up",
			                  "trgcom",
			                  "cc";       /* in zephyr/dts/arm/gd/gd32a50x/gd32a50x.dtsi:345 */
			clocks = < &cctl 0x60d >;     /* in zephyr/dts/arm/gd/gd32a50x/gd32a50x.dtsi:346 */
			resets = < &rctl 0x30d >;     /* in zephyr/dts/arm/gd/gd32a50x/gd32a50x.dtsi:347 */
			is-advanced;                  /* in zephyr/dts/arm/gd/gd32a50x/gd32a50x.dtsi:348 */
			channels = < 0x4 >;           /* in zephyr/dts/arm/gd/gd32a50x/gd32a50x.dtsi:349 */
			status = "disabled";          /* in zephyr/dts/arm/gd/gd32a50x/gd32a50x.dtsi:350 */

			/* node '/soc/timer@40013400/pwm' defined in zephyr/dts/arm/gd/gd32a50x/gd32a50x.dtsi:352 */
			pwm {
				compatible = "gd,gd32-pwm"; /* in zephyr/dts/arm/gd/gd32a50x/gd32a50x.dtsi:353 */
				status = "disabled";        /* in zephyr/dts/arm/gd/gd32a50x/gd32a50x.dtsi:354 */
				#pwm-cells = < 0x3 >;       /* in zephyr/dts/arm/gd/gd32a50x/gd32a50x.dtsi:355 */
			};
		};

		/* node '/soc/timer@40015000' defined in zephyr/dts/arm/gd/gd32a50x/gd32a50x.dtsi:359 */
		timer19: timer@40015000 {
			compatible = "gd,gd32-timer"; /* in zephyr/dts/arm/gd/gd32a50x/gd32a50x.dtsi:360 */
			reg = < 0x40015000 0x400 >;   /* in zephyr/dts/arm/gd/gd32a50x/gd32a50x.dtsi:361 */
			interrupts = < 0x2b 0x0 >;    /* in zephyr/dts/arm/gd/gd32a50x/gd32a50x.dtsi:362 */
			interrupt-names = "global";   /* in zephyr/dts/arm/gd/gd32a50x/gd32a50x.dtsi:363 */
			clocks = < &cctl 0x614 >;     /* in zephyr/dts/arm/gd/gd32a50x/gd32a50x.dtsi:364 */
			resets = < &rctl 0x314 >;     /* in zephyr/dts/arm/gd/gd32a50x/gd32a50x.dtsi:365 */
			channels = < 0x2 >;           /* in zephyr/dts/arm/gd/gd32a50x/gd32a50x.dtsi:366 */
			status = "disabled";          /* in zephyr/dts/arm/gd/gd32a50x/gd32a50x.dtsi:367 */

			/* node '/soc/timer@40015000/pwm' defined in zephyr/dts/arm/gd/gd32a50x/gd32a50x.dtsi:369 */
			pwm {
				compatible = "gd,gd32-pwm"; /* in zephyr/dts/arm/gd/gd32a50x/gd32a50x.dtsi:370 */
				status = "disabled";        /* in zephyr/dts/arm/gd/gd32a50x/gd32a50x.dtsi:371 */
				#pwm-cells = < 0x3 >;       /* in zephyr/dts/arm/gd/gd32a50x/gd32a50x.dtsi:372 */
			};
		};

		/* node '/soc/timer@40015400' defined in zephyr/dts/arm/gd/gd32a50x/gd32a50x.dtsi:376 */
		timer20: timer@40015400 {
			compatible = "gd,gd32-timer"; /* in zephyr/dts/arm/gd/gd32a50x/gd32a50x.dtsi:377 */
			reg = < 0x40015400 0x400 >;   /* in zephyr/dts/arm/gd/gd32a50x/gd32a50x.dtsi:378 */
			interrupts = < 0x2c 0x0 >;    /* in zephyr/dts/arm/gd/gd32a50x/gd32a50x.dtsi:379 */
			interrupt-names = "global";   /* in zephyr/dts/arm/gd/gd32a50x/gd32a50x.dtsi:380 */
			clocks = < &cctl 0x615 >;     /* in zephyr/dts/arm/gd/gd32a50x/gd32a50x.dtsi:381 */
			resets = < &rctl 0x315 >;     /* in zephyr/dts/arm/gd/gd32a50x/gd32a50x.dtsi:382 */
			channels = < 0x1 >;           /* in zephyr/dts/arm/gd/gd32a50x/gd32a50x.dtsi:383 */
			status = "disabled";          /* in zephyr/dts/arm/gd/gd32a50x/gd32a50x.dtsi:384 */

			/* node '/soc/timer@40015400/pwm' defined in zephyr/dts/arm/gd/gd32a50x/gd32a50x.dtsi:386 */
			pwm {
				compatible = "gd,gd32-pwm"; /* in zephyr/dts/arm/gd/gd32a50x/gd32a50x.dtsi:387 */
				status = "disabled";        /* in zephyr/dts/arm/gd/gd32a50x/gd32a50x.dtsi:388 */
				#pwm-cells = < 0x3 >;       /* in zephyr/dts/arm/gd/gd32a50x/gd32a50x.dtsi:389 */
			};
		};

		/* node '/soc/dma@40020000' defined in zephyr/dts/arm/gd/gd32a50x/gd32a50x.dtsi:393 */
		dma0: dma@40020000 {
			compatible = "gd,gd32-dma"; /* in zephyr/dts/arm/gd/gd32a50x/gd32a50x.dtsi:394 */
			reg = < 0x40020000 0x400 >; /* in zephyr/dts/arm/gd/gd32a50x/gd32a50x.dtsi:395 */
			interrupts = < 0xb 0x0 >,
			             < 0xc 0x0 >,
			             < 0xd 0x0 >,
			             < 0xe 0x0 >,
			             < 0xf 0x0 >,
			             < 0x10 0x0 >,
			             < 0x11 0x0 >,
			             < 0x2f 0x0 >;  /* in zephyr/dts/arm/gd/gd32a50x/gd32a50x.dtsi:396 */
			clocks = < &cctl 0x500 >;   /* in zephyr/dts/arm/gd/gd32a50x/gd32a50x.dtsi:398 */
			dma-channels = < 0x7 >;     /* in zephyr/dts/arm/gd/gd32a50x/gd32a50x.dtsi:399 */
			gd,mem2mem;                 /* in zephyr/dts/arm/gd/gd32a50x/gd32a50x.dtsi:400 */
			#dma-cells = < 0x2 >;       /* in zephyr/dts/arm/gd/gd32a50x/gd32a50x.dtsi:401 */
			status = "disabled";        /* in zephyr/dts/arm/gd/gd32a50x/gd32a50x.dtsi:402 */
		};

		/* node '/soc/dma@40020400' defined in zephyr/dts/arm/gd/gd32a50x/gd32a50x.dtsi:405 */
		dma1: dma@40020400 {
			compatible = "gd,gd32-dma"; /* in zephyr/dts/arm/gd/gd32a50x/gd32a50x.dtsi:406 */
			reg = < 0x40020400 0x400 >; /* in zephyr/dts/arm/gd/gd32a50x/gd32a50x.dtsi:407 */
			interrupts = < 0x38 0x0 >,
			             < 0x39 0x0 >,
			             < 0x3a 0x0 >,
			             < 0x3b 0x0 >,
			             < 0x3c 0x0 >;  /* in zephyr/dts/arm/gd/gd32a50x/gd32a50x.dtsi:408 */
			clocks = < &cctl 0x501 >;   /* in zephyr/dts/arm/gd/gd32a50x/gd32a50x.dtsi:410 */
			dma-channels = < 0x5 >;     /* in zephyr/dts/arm/gd/gd32a50x/gd32a50x.dtsi:411 */
			gd,mem2mem;                 /* in zephyr/dts/arm/gd/gd32a50x/gd32a50x.dtsi:412 */
			#dma-cells = < 0x2 >;       /* in zephyr/dts/arm/gd/gd32a50x/gd32a50x.dtsi:413 */
			status = "disabled";        /* in zephyr/dts/arm/gd/gd32a50x/gd32a50x.dtsi:414 */
		};
	};

	/* node '/cpus' defined in zephyr/dts/arm/gd/gd32a50x/gd32a50x.dtsi:17 */
	cpus {
		#address-cells = < 0x1 >; /* in zephyr/dts/arm/gd/gd32a50x/gd32a50x.dtsi:18 */
		#size-cells = < 0x0 >;    /* in zephyr/dts/arm/gd/gd32a50x/gd32a50x.dtsi:19 */

		/* node '/cpus/cpu@0' defined in zephyr/dts/arm/gd/gd32a50x/gd32a50x.dtsi:21 */
		cpu0: cpu@0 {
			compatible = "arm,cortex-m33f";  /* in zephyr/dts/arm/gd/gd32a50x/gd32a50x.dtsi:22 */
			reg = < 0x0 >;                   /* in zephyr/dts/arm/gd/gd32a50x/gd32a50x.dtsi:23 */
			#address-cells = < 0x1 >;        /* in zephyr/dts/arm/gd/gd32a50x/gd32a50x.dtsi:24 */
			#size-cells = < 0x1 >;           /* in zephyr/dts/arm/gd/gd32a50x/gd32a50x.dtsi:25 */
			clock-frequency = < 0x5f5e100 >; /* in zephyr/dts/arm/gd/gd32a50x/gd32a50x.dtsi:26 */

			/* node '/cpus/cpu@0/mpu@e000ed90' defined in zephyr/dts/arm/gd/gd32a50x/gd32a50x.dtsi:28 */
			mpu: mpu@e000ed90 {
				compatible = "arm,armv8m-mpu"; /* in zephyr/dts/arm/gd/gd32a50x/gd32a50x.dtsi:29 */
				reg = < 0xe000ed90 0x40 >;     /* in zephyr/dts/arm/gd/gd32a50x/gd32a50x.dtsi:30 */
			};
		};
	};

	/* node '/leds' defined in zephyr/boards/gd/gd32a503v_eval/gd32a503v_eval.dts:23 */
	leds {
		compatible = "gpio-leds"; /* in zephyr/boards/gd/gd32a503v_eval/gd32a503v_eval.dts:24 */

		/* node '/leds/led1' defined in zephyr/boards/gd/gd32a503v_eval/gd32a503v_eval.dts:26 */
		led1: led1 {
			gpios = < &gpioc 0x0 0x1 >; /* in zephyr/boards/gd/gd32a503v_eval/gd32a503v_eval.dts:27 */
			label = "LED1";             /* in zephyr/boards/gd/gd32a503v_eval/gd32a503v_eval.dts:28 */
		};

		/* node '/leds/led2' defined in zephyr/boards/gd/gd32a503v_eval/gd32a503v_eval.dts:31 */
		led2: led2 {
			gpios = < &gpioc 0x1 0x1 >; /* in zephyr/boards/gd/gd32a503v_eval/gd32a503v_eval.dts:32 */
			label = "LED2";             /* in zephyr/boards/gd/gd32a503v_eval/gd32a503v_eval.dts:33 */
		};
	};
};
